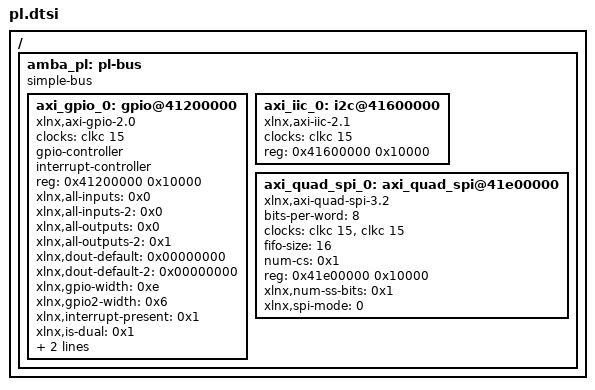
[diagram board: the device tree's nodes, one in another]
/*
 * CAUTION: This file is automatically generated by Xilinx.
 * Version: XSCT 
 * Today is: Tue Jul 29 21:42:08 2025
 */


/ {
	amba_pl: pl-bus {
		#address-cells = <1>;
		#size-cells = <1>;
		compatible = "simple-bus";
		ranges ;
		axi_gpio_0: gpio@41200000 {
			#gpio-cells = <2>;
			#interrupt-cells = <2>;
			clock-names = "s_axi_aclk";
			clocks = <&clkc 15>;
			compatible = "xlnx,axi-gpio-2.0", "xlnx,xps-gpio-1.00.a";
			gpio-controller ;
			interrupt-controller ;
			reg = <0x41200000 0x10000>;
			xlnx,all-inputs = <0x0>;
			xlnx,all-inputs-2 = <0x0>;
			xlnx,all-outputs = <0x0>;
			xlnx,all-outputs-2 = <0x1>;
			xlnx,dout-default = <0x00000000>;
			xlnx,dout-default-2 = <0x00000000>;
			xlnx,gpio-width = <0xe>;
			xlnx,gpio2-width = <0x6>;
			xlnx,interrupt-present = <0x1>;
			xlnx,is-dual = <0x1>;
			xlnx,tri-default = <0xFFFFFFFF>;
			xlnx,tri-default-2 = <0xFFFFFFFF>;
		};
		axi_iic_0: i2c@41600000 {
			#address-cells = <1>;
			#size-cells = <0>;
			clock-names = "s_axi_aclk";
			clocks = <&clkc 15>;
			compatible = "xlnx,axi-iic-2.1", "xlnx,xps-iic-2.00.a";
			reg = <0x41600000 0x10000>;
		};
		axi_quad_spi_0: axi_quad_spi@41e00000 {
			bits-per-word = <8>;
			clock-names = "ext_spi_clk", "s_axi_aclk";
			clocks = <&clkc 15>, <&clkc 15>;
			compatible = "xlnx,axi-quad-spi-3.2", "xlnx,xps-spi-2.00.a";
			fifo-size = <16>;
			num-cs = <0x1>;
			reg = <0x41e00000 0x10000>;
			xlnx,num-ss-bits = <0x1>;
			xlnx,spi-mode = <0>;
		};
	};
};
